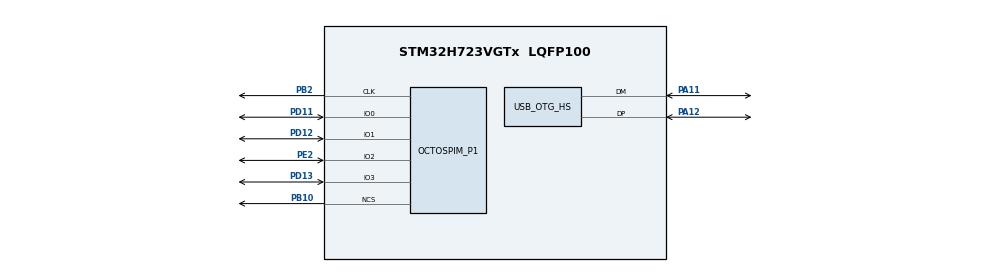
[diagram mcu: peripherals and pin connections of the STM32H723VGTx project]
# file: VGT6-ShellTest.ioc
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CORTEX_M7.default_mode_Activation=1
FREERTOS.Tasks01=defaultTask,24,128,StartDefaultTask,Default,NULL,Dynamic,NULL,NULL
FREERTOS.configCHECK_FOR_STACK_OVERFLOW=2
FREERTOS.configENABLE_FPU=1
FREERTOS.configGENERATE_RUN_TIME_STATS=1
FREERTOS.configUSE_STATS_FORMATTING_FUNCTIONS=1
Mcu.Family=STM32H7
Mcu.Name=STM32H723VGTx
Mcu.Package=LQFP100
Mdma.MDMA_Channel0.OCTOSPI1_FIFO_TH.0.BlockCount=0
Mdma.MDMA_Channel0.OCTOSPI1_FIFO_TH.0.BlockDataLength=0
Mdma.MDMA_Channel0.OCTOSPI1_FIFO_TH.0.BufferTransferLength=1
Mdma.MDMA_Channel0.OCTOSPI1_FIFO_TH.0.CircularMode=MDMA_LINEAR_LIST
Mdma.MDMA_Channel0.OCTOSPI1_FIFO_TH.0.DataAlignment=MDMA_DATAALIGN_PACKENABLE
Mdma.MDMA_Channel0.OCTOSPI1_FIFO_TH.0.DestBlockAddressOffset=0
Mdma.MDMA_Channel0.OCTOSPI1_FIFO_TH.0.DestBurst=MDMA_DEST_BURST_SINGLE
Mdma.MDMA_Channel0.OCTOSPI1_FIFO_TH.0.DestDataSize=MDMA_DEST_DATASIZE_BYTE
Mdma.MDMA_Channel0.OCTOSPI1_FIFO_TH.0.DestinationInc=MDMA_DEST_INC_BYTE
Mdma.MDMA_Channel0.OCTOSPI1_FIFO_TH.0.DstAddress=0
Mdma.MDMA_Channel0.OCTOSPI1_FIFO_TH.0.Endianness=MDMA_LITTLE_ENDIANNESS_PRESERVE
Mdma.MDMA_Channel0.OCTOSPI1_FIFO_TH.0.Instance=MDMA_Channel0
Mdma.MDMA_Channel0.OCTOSPI1_FIFO_TH.0.MaskAddress=0
Mdma.MDMA_Channel0.OCTOSPI1_FIFO_TH.0.MaskData=0
Mdma.MDMA_Channel0.OCTOSPI1_FIFO_TH.0.Priority=MDMA_PRIORITY_LOW
Mdma.MDMA_Channel0.OCTOSPI1_FIFO_TH.0.Rank=First
Mdma.MDMA_Channel0.OCTOSPI1_FIFO_TH.0.SourceBlockAddressOffset=0
Mdma.MDMA_Channel0.OCTOSPI1_FIFO_TH.0.SourceBurst=MDMA_SOURCE_BURST_SINGLE
Mdma.MDMA_Channel0.OCTOSPI1_FIFO_TH.0.SourceDataSize=MDMA_SRC_DATASIZE_BYTE
Mdma.MDMA_Channel0.OCTOSPI1_FIFO_TH.0.SourceInc=MDMA_SRC_INC_BYTE
Mdma.MDMA_Channel0.OCTOSPI1_FIFO_TH.0.SrcAddress=0
Mdma.MDMA_Channel0.OCTOSPI1_FIFO_TH.0.TransferTriggerMode=MDMA_BUFFER_TRANSFER
Mdma.MDMA_Channel0.Request0=OCTOSPI1_FIFO_TH
Mdma.MDMA_Channel0.RequestsNb=1
Mdma.RequestSet0=MDMA_Channel0
Mdma.RequestSetsNb=1
NVIC.MDMA_IRQn=true\:5\:0\:false\:false\:true\:false\:false\:true\:true
NVIC.OCTOSPI1_IRQn=true\:5\:0\:false\:false\:true\:true\:true\:true\:true
NVIC.OTG_HS_IRQn=true\:5\:0\:false\:false\:true\:true\:false\:true\:true
NVIC.PriorityGroup=NVIC_PRIORITYGROUP_4
NVIC.TIM1_UP_IRQn=true\:5\:0\:true\:false\:true\:false\:false\:true\:true
NVIC.TIM2_IRQn=true\:5\:0\:false\:false\:true\:true\:true\:true\:true
NVIC.TimeBase=TIM1_UP_IRQn
NVIC.TimeBaseIP=TIM1
OCTOSPI1.ClockPrescaler=255
OCTOSPI1.FifoThreshold=1
PA11.Mode=Device_Only_FS
PA11.Signal=USB_OTG_HS_DM
PA12.Mode=Device_Only_FS
PA12.Signal=USB_OTG_HS_DP
PA13(JTMS/SWDIO).Mode=Trace_Asynchronous_SW
PA13(JTMS/SWDIO).Signal=DEBUG_JTMS-SWDIO
PA14(JTCK/SWCLK).Mode=Trace_Asynchronous_SW
PA14(JTCK/SWCLK).Signal=DEBUG_JTCK-SWCLK
PB10.Mode=OCTOSPI1_Port1_NCS
PB10.Signal=OCTOSPIM_P1_NCS
PB2.Mode=O1_P1_CLK
PB2.Signal=OCTOSPIM_P1_CLK
PB3(JTDO/TRACESWO).Mode=Trace_Asynchronous_SW
PB3(JTDO/TRACESWO).Signal=DEBUG_JTDO-SWO
PD11.Mode=OCTOSPI1_IOL_Port1L
PD11.Signal=OCTOSPIM_P1_IO0
PD12.Mode=OCTOSPI1_IOL_Port1L
PD12.Signal=OCTOSPIM_P1_IO1
PD13.Mode=OCTOSPI1_IOL_Port1L
PD13.Signal=OCTOSPIM_P1_IO3
PE2.Mode=OCTOSPI1_IOL_Port1L
PE2.Signal=OCTOSPIM_P1_IO2
PH0-OSC_IN.Mode=HSE-External-Oscillator
PH0-OSC_IN.Signal=RCC_OSC_IN
PH1-OSC_OUT.Mode=HSE-External-Oscillator
PH1-OSC_OUT.Signal=RCC_OSC_OUT
ProjectManager.HeapSize=0x200
ProjectManager.StackSize=0x400
ProjectManager.TargetToolchain=CMake
RCC.ADCFreq_Value=50390625
RCC.APB1Freq_Value=137500000
RCC.APB2Freq_Value=137500000
RCC.APB3Freq_Value=137500000
RCC.APB4Freq_Value=137500000
RCC.CortexFreq_Value=550000000
RCC.D1PPRE=RCC_APB3_DIV2
RCC.D2PPRE1=RCC_APB1_DIV2
RCC.D2PPRE2=RCC_APB2_DIV2
RCC.D3PPRE=RCC_APB4_DIV2
RCC.DIVM1=2
RCC.DIVN1=44
RCC.DIVP1=1
RCC.DIVQ1=5
RCC.HCLKFreq_Value=275000000
RCC.HPRE=RCC_HCLK_DIV2
RCC.PLL2FRACN=0
RCC.PLL3FRACN=0
RCC.PLLFRACN=0
RCC.PLLSourceVirtual=RCC_PLLSOURCE_HSE
RCC.SYSCLKFreq_VALUE=550000000
RCC.SYSCLKSource=RCC_SYSCLKSOURCE_PLLCLK
RCC.USBCLockSelection=RCC_USBCLKSOURCE_HSI48
RCC.USBFreq_Value=48000000
TIM2.Prescaler=275
USB_DEVICE.CLASS_NAME_HS=CDC
USB_DEVICE.VirtualMode=Cdc
USB_DEVICE.VirtualModeHS=Cdc_HS
USB_OTG_HS.VirtualMode-Device_Only_FS=Device_Only_FS
VP_FREERTOS_VS_CMSIS_V2.Mode=CMSIS_V2
VP_MEMORYMAP_VS_MEMORYMAP.Mode=CurAppReg
VP_OCTOSPI1_VS_octo.Mode=octo_mode
VP_SYS_VS_tim1.Mode=TIM1
VP_TIM2_VS_ClockSourceINT.Mode=Internal
VP_USB_DEVICE_VS_USB_DEVICE_CDC_HS.Mode=CDC_HS
board=custom

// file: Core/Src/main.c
/* USER CODE BEGIN Header */
/**
  ******************************************************************************
  * @file           : main.c
  * @brief          : Main program body
  ******************************************************************************
  * @attention
  *
  * Copyright (c) 2025 STMicroelectronics.
  * All rights reserved.
  *
  * This software is licensed under terms that can be found in the LICENSE file
  * in the root directory of this software component.
  * If no LICENSE file comes with this software, it is provided AS-IS.
  *
  ******************************************************************************
  */
/* USER CODE END Header */
#include "main.h"
#include "cmsis_os.h"
#include "mdma.h"
#include "octospi.h"
#include "tim.h"
#include "usb_device.h"
#include "gpio.h"

void SystemClock_Config(void);
static void MPU_Config(void);
void MX_FREERTOS_Init(void);

/* USER CODE BEGIN 0 */
void configureTimerForRunTimeStats(void) {
  HAL_TIM_Base_Start(&htim2);
}

unsigned long getRunTimeCounterValue(void) {
  return TIM2->CNT;
}
/* USER CODE END 0 */

int main(void)
{

  /* MPU Configuration--------------------------------------------------------*/
  MPU_Config();

  /* MCU Configuration--------------------------------------------------------*/

  /* Reset of all peripherals, Initializes the Flash interface and the Systick. */
  HAL_Init();

  /* Configure the system clock */
  SystemClock_Config();

  /* Initialize all configured peripherals */
  MX_GPIO_Init();
  MX_MDMA_Init();
  MX_OCTOSPI1_Init();
  MX_TIM2_Init();

  /* Init scheduler */
  osKernelInitialize();  /* Call init function for freertos objects (in cmsis_os2.c) */
  MX_FREERTOS_Init();

  /* Start scheduler */
  osKernelStart();

  /* We should never get here as control is now taken by the scheduler */

  /* Infinite loop */
  while (1)
  {

  }
}

void SystemClock_Config(void)
{
  RCC_OscInitTypeDef RCC_OscInitStruct = {0};
  RCC_ClkInitTypeDef RCC_ClkInitStruct = {0};

  /** Supply configuration update enable
  */
  HAL_PWREx_ConfigSupply(PWR_LDO_SUPPLY);

  /** Configure the main internal regulator output voltage
  */
  __HAL_PWR_VOLTAGESCALING_CONFIG(PWR_REGULATOR_VOLTAGE_SCALE0);

  while(!__HAL_PWR_GET_FLAG(PWR_FLAG_VOSRDY)) {}

  /** Initializes the RCC Oscillators according to the specified parameters
  * in the RCC_OscInitTypeDef structure.
  */
  RCC_OscInitStruct.OscillatorType = RCC_OSCILLATORTYPE_HSI48|RCC_OSCILLATORTYPE_HSE;
  RCC_OscInitStruct.HSEState = RCC_HSE_ON;
  RCC_OscInitStruct.HSI48State = RCC_HSI48_ON;
  RCC_OscInitStruct.PLL.PLLState = RCC_PLL_ON;
  RCC_OscInitStruct.PLL.PLLSource = RCC_PLLSOURCE_HSE;
  RCC_OscInitStruct.PLL.PLLM = 2;
  RCC_OscInitStruct.PLL.PLLN = 44;
  RCC_OscInitStruct.PLL.PLLP = 1;
  RCC_OscInitStruct.PLL.PLLQ = 5;
  RCC_OscInitStruct.PLL.PLLR = 2;
  RCC_OscInitStruct.PLL.PLLRGE = RCC_PLL1VCIRANGE_3;
  RCC_OscInitStruct.PLL.PLLVCOSEL = RCC_PLL1VCOWIDE;
  RCC_OscInitStruct.PLL.PLLFRACN = 0;
  if (HAL_RCC_OscConfig(&RCC_OscInitStruct) != HAL_OK)
  {
    Error_Handler();
  }

  /** Initializes the CPU, AHB and APB buses clocks
  */
  RCC_ClkInitStruct.ClockType = RCC_CLOCKTYPE_HCLK|RCC_CLOCKTYPE_SYSCLK
                              |RCC_CLOCKTYPE_PCLK1|RCC_CLOCKTYPE_PCLK2
                              |RCC_CLOCKTYPE_D3PCLK1|RCC_CLOCKTYPE_D1PCLK1;
  RCC_ClkInitStruct.SYSCLKSource = RCC_SYSCLKSOURCE_PLLCLK;
  RCC_ClkInitStruct.SYSCLKDivider = RCC_SYSCLK_DIV1;
  RCC_ClkInitStruct.AHBCLKDivider = RCC_HCLK_DIV2;
  RCC_ClkInitStruct.APB3CLKDivider = RCC_APB3_DIV2;
  RCC_ClkInitStruct.APB1CLKDivider = RCC_APB1_DIV2;
  RCC_ClkInitStruct.APB2CLKDivider = RCC_APB2_DIV2;
  RCC_ClkInitStruct.APB4CLKDivider = RCC_APB4_DIV2;

  if (HAL_RCC_ClockConfig(&RCC_ClkInitStruct, FLASH_LATENCY_3) != HAL_OK)
  {
    Error_Handler();
  }
}

 /* MPU Configuration */

void MPU_Config(void)
{
  MPU_Region_InitTypeDef MPU_InitStruct = {0};

  /* Disables the MPU */
  HAL_MPU_Disable();

  /** Initializes and configures the Region and the memory to be protected
  */
  MPU_InitStruct.Enable = MPU_REGION_ENABLE;
  MPU_InitStruct.Number = MPU_REGION_NUMBER0;
  MPU_InitStruct.BaseAddress = 0x0;
  MPU_InitStruct.Size = MPU_REGION_SIZE_4GB;
  MPU_InitStruct.SubRegionDisable = 0x87;
  MPU_InitStruct.TypeExtField = MPU_TEX_LEVEL0;
  MPU_InitStruct.AccessPermission = MPU_REGION_NO_ACCESS;
  MPU_InitStruct.DisableExec = MPU_INSTRUCTION_ACCESS_DISABLE;
  MPU_InitStruct.IsShareable = MPU_ACCESS_SHAREABLE;
  MPU_InitStruct.IsCacheable = MPU_ACCESS_NOT_CACHEABLE;
  MPU_InitStruct.IsBufferable = MPU_ACCESS_NOT_BUFFERABLE;

  HAL_MPU_ConfigRegion(&MPU_InitStruct);
  /* Enables the MPU */
  HAL_MPU_Enable(MPU_PRIVILEGED_DEFAULT);

}

void HAL_TIM_PeriodElapsedCallback(TIM_HandleTypeDef *htim)
{
  if (htim->Instance == TIM1)
  {
    HAL_IncTick();
  }
}

void Error_Handler(void)
{
  __disable_irq();
  while (1)
  {
  }
}
